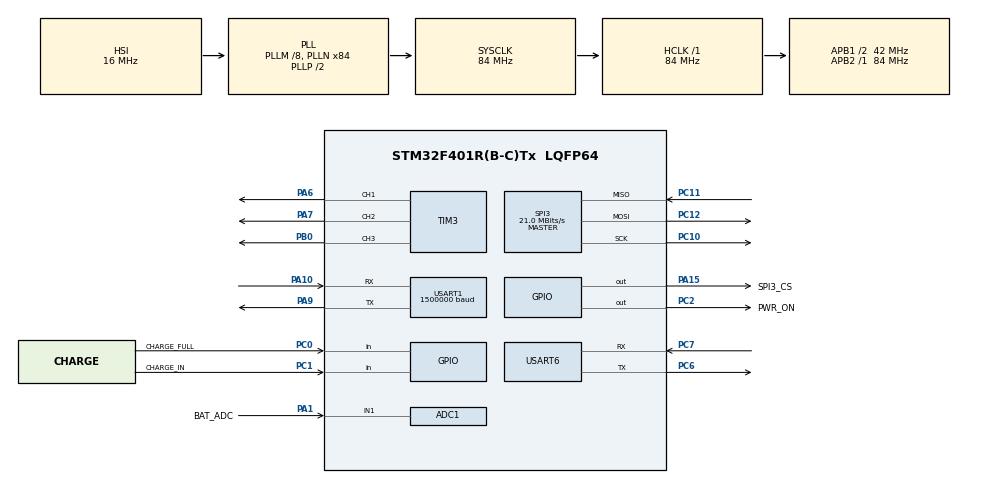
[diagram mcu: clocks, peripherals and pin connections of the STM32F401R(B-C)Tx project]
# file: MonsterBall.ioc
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ADC1.Channel-1\#ChannelRegularConversion=ADC_CHANNEL_1
ADC1.ContinuousConvMode=ENABLE
ADC1.NbrOfConversionFlag=1
ADC1.Rank-1\#ChannelRegularConversion=1
ADC1.SamplingTime-1\#ChannelRegularConversion=ADC_SAMPLETIME_3CYCLES
ADC1.master=1
Dma.ADC1.0.Direction=DMA_PERIPH_TO_MEMORY
Dma.ADC1.0.FIFOMode=DMA_FIFOMODE_DISABLE
Dma.ADC1.0.Instance=DMA2_Stream0
Dma.ADC1.0.MemDataAlignment=DMA_MDATAALIGN_HALFWORD
Dma.ADC1.0.MemInc=DMA_MINC_ENABLE
Dma.ADC1.0.Mode=DMA_CIRCULAR
Dma.ADC1.0.PeriphDataAlignment=DMA_PDATAALIGN_HALFWORD
Dma.ADC1.0.PeriphInc=DMA_PINC_DISABLE
Dma.ADC1.0.Priority=DMA_PRIORITY_LOW
Dma.Request0=ADC1
FREERTOS.Tasks01=defaultTask,24,128,StartDefaultTask,Default,NULL,Dynamic,NULL,NULL
FREERTOS.configENABLE_FPU=1
Mcu.Family=STM32F4
Mcu.Name=STM32F401R(B-C)Tx
Mcu.Package=LQFP64
NVIC.DMA2_Stream0_IRQn=true\:5\:0\:false\:false\:true\:true\:false\:true\:true
NVIC.PriorityGroup=NVIC_PRIORITYGROUP_4
NVIC.TIM5_IRQn=true\:15\:0\:false\:false\:true\:false\:false\:true\:true
NVIC.TimeBase=TIM5_IRQn
NVIC.TimeBaseIP=TIM5
PA1.GPIO_Label=BAT_ADC
PA1.Signal=ADCx_IN1
PA10.Mode=Asynchronous
PA10.Signal=USART1_RX
PA13.Mode=Serial_Wire
PA13.Signal=SYS_JTMS-SWDIO
PA14.Mode=Serial_Wire
PA14.Signal=SYS_JTCK-SWCLK
PA15.GPIO_Label=SPI3_CS
PA15.GPIO_PuPd=GPIO_PULLUP
PA15.Signal=GPIO_Output
PA6.Signal=S_TIM3_CH1
PA7.Signal=S_TIM3_CH2
PA9.Mode=Asynchronous
PA9.Signal=USART1_TX
PB0.Signal=S_TIM3_CH3
PC0.GPIO_Label=CHARGE_FULL
PC0.GPIO_PuPd=GPIO_PULLDOWN
PC0.Signal=GPIO_Input
PC1.GPIO_Label=CHARGE_IN
PC1.GPIO_PuPd=GPIO_PULLDOWN
PC1.Signal=GPIO_Input
PC10.Mode=Full_Duplex_Master
PC10.Signal=SPI3_SCK
PC11.Mode=Full_Duplex_Master
PC11.Signal=SPI3_MISO
PC12.Mode=Full_Duplex_Master
PC12.Signal=SPI3_MOSI
PC2.GPIO_Label=PWR_ON
PC2.Signal=GPIO_Output
PC6.Mode=Asynchronous
PC6.Signal=USART6_TX
PC7.Mode=Asynchronous
PC7.Signal=USART6_RX
ProjectManager.HeapSize=0x200
ProjectManager.StackSize=0x400
ProjectManager.TargetToolchain=MDK-ARM V5.32
RCC.48MHZClocksFreq_Value=42000000
RCC.AHBFreq_Value=84000000
RCC.APB1CLKDivider=RCC_HCLK_DIV2
RCC.APB1Freq_Value=42000000
RCC.APB1TimFreq_Value=84000000
RCC.APB2Freq_Value=84000000
RCC.APB2TimFreq_Value=84000000
RCC.CortexFreq_Value=84000000
RCC.HCLKFreq_Value=84000000
RCC.HSE_VALUE=25000000
RCC.HSI_VALUE=16000000
RCC.LSE_VALUE=32768
RCC.PLLM=8
RCC.PLLN=84
RCC.SYSCLKFreq_VALUE=84000000
RCC.SYSCLKSource=RCC_SYSCLKSOURCE_PLLCLK
RCC.VCOOutputFreq_Value=168000000
SH.ADCx_IN1.0=ADC1_IN1,IN1
SH.S_TIM3_CH1.0=TIM3_CH1,PWM Generation1 CH1
SH.S_TIM3_CH2.0=TIM3_CH2,PWM Generation2 CH2
SH.S_TIM3_CH3.0=TIM3_CH3,PWM Generation3 CH3
SPI3.CalculateBaudRate=21.0 MBits/s
SPI3.Direction=SPI_DIRECTION_2LINES
SPI3.Mode=SPI_MODE_MASTER
SPI3.VirtualType=VM_MASTER
TIM3.Channel-PWM\ Generation1\ CH1=TIM_CHANNEL_1
TIM3.Channel-PWM\ Generation2\ CH2=TIM_CHANNEL_2
TIM3.Channel-PWM\ Generation3\ CH3=TIM_CHANNEL_3
USART1.BaudRate=1500000
USART1.VirtualMode=VM_ASYNC
USART6.VirtualMode=VM_ASYNC
VP_FREERTOS_VS_CMSIS_V2.Mode=CMSIS_V2
VP_SYS_VS_tim5.Mode=TIM5
board=custom

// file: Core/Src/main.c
/* USER CODE BEGIN Header */
/**
  ******************************************************************************
  * @file           : main.c
  * @brief          : Main program body
  ******************************************************************************
  * @attention
  *
  * Copyright (c) 2025 STMicroelectronics.
  * All rights reserved.
  *
  * This software is licensed under terms that can be found in the LICENSE file
  * in the root directory of this software component.
  * If no LICENSE file comes with this software, it is provided AS-IS.
  *
  ******************************************************************************
  */
/* USER CODE END Header */
#include "main.h"
#include "cmsis_os.h"
#include "adc.h"
#include "dma.h"
#include "spi.h"
#include "tim.h"
#include "usart.h"
#include "gpio.h"

void SystemClock_Config(void);
void MX_FREERTOS_Init(void);

int main(void)
{

  /* MCU Configuration--------------------------------------------------------*/

  /* Reset of all peripherals, Initializes the Flash interface and the Systick. */
  HAL_Init();

  /* Configure the system clock */
  SystemClock_Config();

  /* Initialize all configured peripherals */
  MX_GPIO_Init();
  MX_DMA_Init();
  MX_USART1_UART_Init();
  MX_ADC1_Init();
  MX_SPI3_Init();
  MX_USART6_UART_Init();
  MX_TIM3_Init();

  /* Init scheduler */
  osKernelInitialize();  /* Call init function for freertos objects (in cmsis_os2.c) */
  MX_FREERTOS_Init();

  /* Start scheduler */
  osKernelStart();

  /* We should never get here as control is now taken by the scheduler */

  /* Infinite loop */
  while (1)
  {

  }
}

void SystemClock_Config(void)
{
  RCC_OscInitTypeDef RCC_OscInitStruct = {0};
  RCC_ClkInitTypeDef RCC_ClkInitStruct = {0};

  /** Configure the main internal regulator output voltage
  */
  __HAL_RCC_PWR_CLK_ENABLE();
  __HAL_PWR_VOLTAGESCALING_CONFIG(PWR_REGULATOR_VOLTAGE_SCALE2);

  /** Initializes the RCC Oscillators according to the specified parameters
  * in the RCC_OscInitTypeDef structure.
  */
  RCC_OscInitStruct.OscillatorType = RCC_OSCILLATORTYPE_HSI;
  RCC_OscInitStruct.HSIState = RCC_HSI_ON;
  RCC_OscInitStruct.HSICalibrationValue = RCC_HSICALIBRATION_DEFAULT;
  RCC_OscInitStruct.PLL.PLLState = RCC_PLL_ON;
  RCC_OscInitStruct.PLL.PLLSource = RCC_PLLSOURCE_HSI;
  RCC_OscInitStruct.PLL.PLLM = 8;
  RCC_OscInitStruct.PLL.PLLN = 84;
  RCC_OscInitStruct.PLL.PLLP = RCC_PLLP_DIV2;
  RCC_OscInitStruct.PLL.PLLQ = 4;
  if (HAL_RCC_OscConfig(&RCC_OscInitStruct) != HAL_OK)
  {
    Error_Handler();
  }

  /** Initializes the CPU, AHB and APB buses clocks
  */
  RCC_ClkInitStruct.ClockType = RCC_CLOCKTYPE_HCLK|RCC_CLOCKTYPE_SYSCLK
                              |RCC_CLOCKTYPE_PCLK1|RCC_CLOCKTYPE_PCLK2;
  RCC_ClkInitStruct.SYSCLKSource = RCC_SYSCLKSOURCE_PLLCLK;
  RCC_ClkInitStruct.AHBCLKDivider = RCC_SYSCLK_DIV1;
  RCC_ClkInitStruct.APB1CLKDivider = RCC_HCLK_DIV2;
  RCC_ClkInitStruct.APB2CLKDivider = RCC_HCLK_DIV1;

  if (HAL_RCC_ClockConfig(&RCC_ClkInitStruct, FLASH_LATENCY_2) != HAL_OK)
  {
    Error_Handler();
  }
}

void HAL_TIM_PeriodElapsedCallback(TIM_HandleTypeDef *htim)
{
  if (htim->Instance == TIM5)
  {
    HAL_IncTick();
  }
}

void Error_Handler(void)
{
  __disable_irq();
  while (1)
  {
  }
}

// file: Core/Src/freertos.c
/* USER CODE BEGIN Header */
/**
  ******************************************************************************
  * File Name          : freertos.c
  * Description        : Code for freertos applications
  ******************************************************************************
  * @attention
  *
  * Copyright (c) 2025 STMicroelectronics.
  * All rights reserved.
  *
  * This software is licensed under terms that can be found in the LICENSE file
  * in the root directory of this software component.
  * If no LICENSE file comes with this software, it is provided AS-IS.
  *
  ******************************************************************************
  */
/* USER CODE END Header */

#include "FreeRTOS.h"
#include "task.h"
#include "main.h"
#include "cmsis_os.h"

/* USER CODE BEGIN Includes */
#include "app/sys_init.h"
/* USER CODE END Includes */

/* Definitions for defaultTask */
osThreadId_t defaultTaskHandle;
const osThreadAttr_t defaultTask_attributes = {
  .name = "defaultTask",
  .stack_size = 128 * 4,
  .priority = (osPriority_t) osPriorityNormal,
};

void StartDefaultTask(void *argument);

void MX_FREERTOS_Init(void); /* (MISRA C 2004 rule 8.1) */

void MX_FREERTOS_Init(void) {

  /* Create the thread(s) */
  /* creation of defaultTask */
  defaultTaskHandle = osThreadNew(StartDefaultTask, NULL, &defaultTask_attributes);

}

void StartDefaultTask(void *argument)
{
  /* USER CODE BEGIN StartDefaultTask */
  SystemInit();
  /* Infinite loop */
  for(;;)
  {
    osDelay(1);
  }
  /* USER CODE END StartDefaultTask */
}
